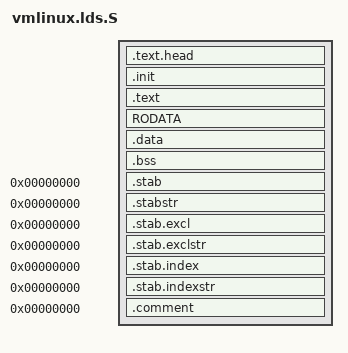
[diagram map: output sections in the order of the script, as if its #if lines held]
/* ld script to make ARM Linux kernel
 * taken from the i386 version by Russell King
 * Written by Martin Mares <mj@atrey.karlin.mff.cuni.cz>
 */

#include <asm-generic/vmlinux.lds.h>
#include <asm/thread_info.h>
#include <asm/memory.h>
	
OUTPUT_ARCH(arm)
ENTRY(stext)

#ifndef __ARMEB__
jiffies = jiffies_64;
#else
jiffies = jiffies_64 + 4;
#endif

SECTIONS
{
#ifdef CONFIG_XIP_KERNEL
	. = XIP_VIRT_ADDR(CONFIG_XIP_PHYS_ADDR);
#else
	. = PAGE_OFFSET + TEXT_OFFSET;
#endif
	.text.head : {
		_stext = .;
		_sinittext = .;
		*(.text.head)
	}

	.init : {			/* Init code and data		*/
			*(.init.text)
		_einittext = .;
		__proc_info_begin = .;
			*(.proc.info.init)
		__proc_info_end = .;
		__arch_info_begin = .;
			*(.arch.info.init)
		__arch_info_end = .;
		__tagtable_begin = .;
			*(.taglist.init)
		__tagtable_end = .;
		. = ALIGN(16);
		__setup_start = .;
			*(.init.setup)
		__setup_end = .;
		__early_begin = .;
			*(.early_param.init)
		__early_end = .;
		__initcall_start = .;
			INITCALLS
		__initcall_end = .;
		__con_initcall_start = .;
			*(.con_initcall.init)
		__con_initcall_end = .;
		__security_initcall_start = .;
			*(.security_initcall.init)
		__security_initcall_end = .;
#ifdef CONFIG_BLK_DEV_INITRD
		. = ALIGN(32);
		__initramfs_start = .;
			usr/built-in.o(.init.ramfs)
		__initramfs_end = .;
#endif
		. = ALIGN(4096);
		__per_cpu_start = .;
			*(.data.percpu)
			*(.data.percpu.shared_aligned)
		__per_cpu_end = .;
#ifndef CONFIG_XIP_KERNEL
		__init_begin = _stext;
		*(.init.data)
		. = ALIGN(4096);
		__init_end = .;
#endif
	}

	/DISCARD/ : {			/* Exit code and data		*/
		*(.exit.text)
		*(.exit.data)
		*(.exitcall.exit)
#ifndef CONFIG_MMU
		*(.fixup)
		*(__ex_table)
#endif
	}

	.text : {			/* Real text segment        */
        	_text = .; 		/* Text and read-only data  */
            *(.text.arm926_dma_clean_range)
            *(.text.arm926_dma_inv_range)
            *(.text.arm926_dma_flush_range)
            *(.text.__irq_svc)
            *(.text.__arch_copy_to_user)
            *(.text.__arch_copy_from_user)
            *(.text.__kmalloc)
            *(.text.OXNAS_unmask_irq)
            *(.text.local_bh_enable)
            *(.text.do_level_IRQ)
            *(.text.__memzero)
            *(.text.irq_exit)
            *(.text.__do_irq)
            *(.text.pfifo_fast_dequeue)
            *(.text.preempt_return)
            *(.text.cpu_arm926_switch_mm)
            *(.text.check_irq_lock)
            *(.text.tcp_init_tso_segs)
            *(.text.kfree_skbmem)
            *(.text.consistent_sync)
            *(.text.__alloc_skb)
            *(.text.skb_release_data)
            *(.text.OXNAS_mask_irq)
            *(.text.Ldiv0)
            *(.text.__do_softirq)
            *(.text.kmem_cache_free)
            *(.text.__kfree_skb)
            *(.text.kmem_cache_alloc)
            *(.text.radix_tree_lookup)
            *(.text.kfree)
            *(.text.asm_do_IRQ)
            *(.text.skb_clone)
            *(.text.qdisc_restart)
            *(.text.sock_wfree)
            *(.text.unlock_page)
            *(.text.tcp_cwnd_validate)
            *(.text.free_hot_cold_page)
            *(.text.memcpy)
            *(.text.velocity_free_tx_buf)
            *(.text.wake_up_bit)
            *(.text.cond_resched)
            *(.text.pfifo_fast_enqueue)
            *(.text.raise_softirq_irqoff)
            *(.text.tcp_push_one)
            *(.text.__modsi3)
            *(.text.update_send_head)
            *(.text.tcp_set_skb_tso_segs)
            *(.text.tcp_snd_test)
            *(.text.svc_preempt)
            *(.text.__tcp_select_window)
            *(.text.dev_queue_xmit)
            *(.text.oxnas_gettimeoffset)
            *(.text.__wake_up_bit)
            *(.text.mod_timer)
            *(.text.do_simple_IRQ)
            *(.text.velocity_xmit)
            *(.text.ip_output)
            *(.text.net_tx_action)
            *(.text.ip_queue_xmit)
            *(.text.tcp_cong_avoid)
            *(.text.sk_reset_timer)
            *(.text.velocity_intr)
            *(.text.pci_dma_sync_single_for_device)
            *(.text.process_backlog)
            *(.text.tcp_v4_send_check)
            *(.text.tcp_transmit_skb)
            *(.text.file_send_actor)
            *(.text.tcp_current_mss)
            *(.text.__netif_rx_schedule)
            *(.text.__muldi3)
            *(.text.release_sock)
            *(.text.do_softirq)
            *(.text.pfifo_fast_reset)
            *(.text.netif_rx)
            *(.text.kernel_sendmsg)
            *(.text.rt_hash_code)
            *(.text.mod_page_state_offset)
            *(.text.preempt_schedule)
            *(.text.inet_sendmsg)
            *(.text.page_waitqueue)
            *(.text.bictcp_acked)
            *(.text.__sk_dst_check)
            *(.text.blk_rq_map_sg)
            *(.text.tcp_mtu_to_mss)
            *(.text.__delay)
            *(.text.sock_sendmsg)
            *(.text.sock_sendpage)
            *(.text.ip_local_deliver)
            *(.text.bio_add_page)
            *(.text.tcp_sendmsg)
            *(.text.sock_no_sendpage)
            *(.text.__remove_from_page_cache)
            *(.text.net_rx_action)
            *(.text.eth_type_trans)
            *(.text.find_get_page)
            *(.text.netif_receive_skb)
            *(.text.verify_chain)
            *(.text.radix_tree_delete)
            *(.text.mpage_readpages)
            *(.text.velocity_rx_refill)
            *(.text.mpage_end_io_read)
            *(.text.radix_tree_insert)
            *(.text.ip_rcv)
            *(.text.register_gifconf)
            *(.text.dma_mmap)
            *(.text.tcp_rtt_estimator)
            *(.text.ox800sata_get_bbp_base)
            *(.text.mark_page_accessed)
            *(.text.update_process_times)
            *(.text.__pagevec_free)
            *(.text.read_page_state_offset)
            *(.text.__bio_add_page)
            *(.text.__pagevec_lru_add)
            *(.text.ox800sata_scr_read)
            *(.text.bio_add_pc_page)
            *(.text.__rcu_pending)
            *(.text.free_sg_entry)
            *(.text.put_page)
            *(.text.lock_timer_base)
            *(.text.radix_tree_tagged)
            *(.text.__lshrdi3)
            *(.text.lock_sock)
            *(.text.__udivsi3)
            *(.text.zone_watermark_ok)
            *(.text.klist_children_put)
            *(.text.sock_aio_dtor)
            *(.text.ata_qc_prep)
            *(.text.oxnas_dma_free)
            *(.text.rcu_pending)
            *(.text.free_cold_page)
            *(.text.get_page_from_freelist)
            *(.text.alloc_sg_entry)
            *(.text.ret_fast_syscall)
            *(.text.add_to_page_cache)
            *(.text.__mod_timer)
            *(.text.velocity_free_td_ring)
            *(.text.__do_div64)
            *(.text.remove_mapping)
            *(.text.fast_work_pending)
            *(.text.cond_resched_softirq)
            *(.text.tcp_v4_rcv)
            *(.text.kernel_recvmsg)
            *(.text.isolate_lru_pages)
            *(.text.klist_children_get)
            *(.text.sys_getpid)
            *(.text.mempool_free_slab)
            *(.text.kobject_get)
            *(.text.__tcp_push_pending_frames)
            *(.text.sk_stop_timer)
            *(.text.bictcp_state)
            *(.text.tcp_check_space)
            *(.text.kmem_cache_zalloc)
            *(.text.get_device)
            *(.text.work_pending)
            *(.text.tcp_ack)
            *(.text.do_edge_IRQ)
            *(.text.page_referenced)
            *(.text.profile_tick)
            *(.text.ox800sata_get_link_base)
            *(.text.__pagevec_release_nonlru)
            *(.text.blk_recount_segments)
            *(.text.__mod_page_state_offset)
            *(.text.linear_mergeable_bvec)
            *(.text.recalc_task_prio)
            *(.text.mempool_kmalloc)
            *(.text.do_mpage_readpage)
            *(.text.ksoftirqd)
            *(.text.__generic_unplug_device)
            *(.text.rt_cpu_seq_start)
            *(.text.bio_alloc)
            *(.text.tasklet_action)
            *(.text.effective_prio)
            *(.text.OXNAS_timer_interrupt)
            *(.text.__wake_up_common)
            *(.text.free_poll_entry)
            *(.text.vector_swi)
            *(.text.do_sock_read)
            *(.text.alloc_sg_controller)
            *(.text.tcp_rcv_established)
            *(.text.oxnas_dma_set_callback)
            *(.text.run_local_timers)
            *(.text.sock_rmalloc)
            *(.text.__rmqueue)
            *(.text.ox800sata_bmdma_start)
            *(.text.fget_light)
            *(.text.queue_work)
            *(.text.mempool_alloc_slab)
            *(.text.__wake_up)
            *(.text.default_idle)
            *(.text.fput)
            *(.text.add_wait_queue)
            *(.text.memcpy_toiovec)
            *(.text.rw_verify_area)
            *(.text.internal_add_timer)
            *(.text.hrtimer_run_queues)
            *(.text.tcp_v4_do_rcv)
            *(.text.raise_softirq)
            *(.text.del_timer)
            *(.text.try_to_wake_up)
            *(.text.__do_page_cache_readahead)
            *(.text.__alloc_pages)
            *(.text.sock_aio_read)
            *(.text.timer_tick)
            *(.text.ox800sata_check_status)
            *(.text.do_generic_mapping_read)
            *(.text.__ox800sata_scr_read)
            *(.text.elv_queue_empty)
            *(.text.do_select)
            *(.text.free_pages_bulk)
            *(.text.remove_wait_queue)
            *(.text.dma_bh)
            *(.text.__irq_usr)
            *(.text.vfs_read)
            *(.text.run_timer_softirq)
            *(.text.radix_tree_preload)
            *(.text.ptrace_getrn)
            *(.text.tcp_dsack_set)
            *(.text.__switch_to)
            *(.text.bio_hw_segments)
            *(.text.__const_udelay)
            *(.text.nr_running)
            *(.text.oxnas_dma_device_set_prd)
            *(.text.kref_put)
            *(.text.enqueue_task)
            *(.text.dequeue_task)
            *(.text.elv_next_request)
            *(.text.profile_hit)
            *(.text.slab_destroy)
            *(.text.schedule)
            *(.text.end_that_request_first)
            *(.text.cfq_find_next_crq)
            *(.text.__freed_request)
            *(.text.adjtime_adjustment)
            *(.text.bictcp_cong_avoid)
            *(.text.kthread_should_stop)
            *(.text.__activate_task)
            *(.text.account_system_time)
            *(.text.bio_fs_destructor)
            *(.text.mempool_alloc)
            *(.text.elv_set_request)
            *(.text.schedule_work)
            *(.text.wake_up_state)
            *(.text.encode_control_status)
            *(.text.alloc_skb_from_cache)
            *(.text.qdisc_lock_tree)
            *(.text.kref_get)
            *(.text.init_timer)
            *(.text.oxnas_dma_is_active)
            *(.text.shrink_slab)
            *(.text.poll_freewait)
            *(.text.sys_fstat64)
            *(.text.__pollwait)
            *(.text.cfq_queue_empty)
            *(.text.linear_issue_flush)
            *(.text.__tasklet_schedule)
            *(.text.ox800sata_get_io_base)
            *(.text.deactivate_task)
            *(.text.cleanup_rbuf)
            *(.text.nr_free_zone_pages)
            *(.text.ip_route_input)
            *(.text.__lock_page)
            *(.text.sock_poll)
            *(.text.__pskb_trim_head)
            *(.text.sys_read)
            *(.text.__arch_copy_to_user)
            *(.text.generic_make_request)
            *(.text.scsi_end_request)
            *(.text.bio_init)
            *(.text.pipefs_delete_dentry)
            *(.text.ox800sata_post_set_mode)
            *(.text.sock_common_recvmsg)
            *(.text.put_device)
            *(.text.tcp_syn_build_options)
            *(.text.scheduler_tick)
            *(.text.__sys_trace)
            *(.text.ox800sata_qc_new)
            *(.text.elv_latter_request)
            *(.text.do_sync_read)
            *(.text.ox800sata_spot_the_end)
            *(.text.get_dirty_limits)
            *(.text.bio_phys_segments)
            *(.text.vfs_fstat)
            *(.text.scsi_finish_command)
            *(.text.wake_up_process)
            *(.text.wdc_ledtrig_sata_activity)
            *(.text.__elv_add_request)
            *(.text.sock_common_setsockopt)
            *(.text.elv_may_queue)
            *(.text.rb_first)
            *(.text.dnotify_parent)
            *(.text.get_writeback_state)
            *(.text.__blk_put_request)
            *(.text.sock_mmap)
            *(.text.throttle_vm_writeout)
            *(.text.drive_stat_acct)
            *(.text.dlci_ioctl_set)
            *(.text.sys_send)
            *(.text.default_wake_function)
            *(.text.cfq_resort_rr_list)
            *(.text.bio_put)
            *(.text.scsi_done)
            *(.text.kobject_put)
            *(.text.release_pages)
            *(.text.ata_qc_issue)
            *(.text.cfq_dispatch_insert)
            *(.text.run_workqueue)
            *(.text.delayed_work_timer_fn)
            *(.text.scsi_init_cmd_errh)
            *(.text.alloc_sock_iocb)
            *(.text.blk_done_softirq)
            *(.text.do_timer)
            *(.text.scsi_10_lba_len)
            *(.text.scsi_device_unbusy)
            *(.text.bio_get_nr_vecs)
            *(.text.cfq_find_cfq_hash)
            *(.text.ata_dev_select)
            *(.text.blk_remove_plug)
            *(.text.end_that_request_last)
            *(.text.shrink_dcache_memory)
            *(.text.elv_put_request)
            *(.text.sys_sendto)
            *(.text.scsi_put_command)
            *(.text._clear_bit_le)
            *(.text.ata_rwcmd_protocol)
            *(.text.kobject_cleanup)
            *(.text.do_sendfile)
            *(.text.worker_thread)
            *(.text.elv_dispatch_sort)
            *(.text.tcp_fast_parse_options)
            *(.text.ox800sata_irq_on)
            *(.text.scsi_request_fn)
            *(.text.ox800sata_irq_handler)
            *(.text.nr_context_switches)
            *(.text.oxnas_dma_request)
            *(.text.sys_sendfile64)
            *(.text.cfq_add_crq_rb)
            *(.text.ata_scsi_queuecmd)
            *(.text.sock_def_readable)
            *(.text.inet_sendpage)
            *(.text.cfq_set_request)
            *(.text.init_request_from_bio)
            *(.text.tcp_v4_conn_request)
            *(.text.requeue_task)
            *(.text.cache_alloc_refill)
            *(.text.scsi_get_command)
            *(.text.blk_complete_request)
            *(.text.scsi_add_timer)
            *(.text.sk_stream_rfree)
            *(.text.__umodsi3)
            *(.text.ox800sata_tf_load)
            *(.text.tcp_recvmsg)
            *(.text.cfq_insert_request)
            *(.text.tcp_sendpage)
            *(.text.bio_alloc_bioset)
            *(.text.__tcp_ack_snd_check)
            *(.text.kthread_bind)
            *(.text.scsi_delete_timer)
            *(.text.ox800sata_dev_config)
            *(.text.add_wait_queue_exclusive)
            *(.text.ox800sata_bmdma_setup)
            *(.text.ox800sata_exec_command)
            *(.text.clear_queue_congested)
            *(.text.generic_file_sendfile)
            *(.text.get_io_context)
            *(.text.swap_buf_le16)
            *(.text._set_bit_be)
            *(.text.led_trigger_event)
            *(.text.current_io_context)
            *(.text.bio_free)
            *(.text.pipe_poll)
            *(.text.freed_request)
            *(.text.cfq_choose_req)
            *(.text.ox800sata_RAID_faults)
            *(.text.rb_prev)
            *(.text.blk_run_queue)
            *(.text.mpage_alloc)
            *(.text.__get_zone_counts)
            *(.text.mpage_bio_submit)
            *(.text.generic_fillattr)
            *(.text.kswapd)
            *(.text.preempt_schedule_irq)
            *(.text.mempool_free)
            *(.text.elv_dequeue_request)
            *(.text.add_interrupt_randomness)
            *(.text.poll_initwait)
            *(.text.__put_user_bad)
            *(.text.vfs_getattr)
            *(.text.scsi_free_sgtable)
            *(.text.laptop_sync_completion)
            *(.text.submit_bio)
            *(.text.sock_from_file)
            *(.text.add_disk_randomness)
            *(.text.scsi_kill_request)
            *(.text.free_hot_page)
            *(.text.bio_endio)
            *(.text.scsi_dispatch_cmd)
            *(.text.oxnas_dma_start)
            *(.text.cfq_remove_request)
            *(.text.do_gettimeofday)
            *(.text.skb_copy_datagram_iovec)
            *(.text.ext3_get_blocks_handle)
            *(.text.__down_read_trylock)
            *(.text.cfq_activate_request)
            *(.text.recalc_sigpending)
            *(.text.ext3_readpage)
            *(.text.ox800sata_dev_select)
            *(.text.ret_to_user)
            *(.text.elv_completed_request)
            *(.text.read_cache_page)
            *(.text.touch_atime)
            *(.text.cfq_update_next_crq)
            *(.text.no_work_pending)
            *(.text.recalc_sigpending_tsk)
            *(.text.end_that_request_chunk)
            *(.text.cp_new_stat64)
            *(.text.rb_next)
            *(.text.__wake_up_sync)
            *(.text.subsys_create_file)
            *(.text.rcu_needs_cpu)
            *(.text.sys_select)
            *(.text.oxnas_dma_device_set)
            *(.text.ata_sg_init)
            *(.text.__put_user_8)
            *(.text.ox800sata_port_disable)
            *(.text.scsi_next_command)
            *(.text.__scsi_done)
            *(.text.ata_scsi_qc_complete)
            *(.text.__wake_up_locked)
            *(.text.lru_add_drain)
            *(.text.bio_check_pages_dirty)
            *(.text.cascade)
            *(.text.tcp_poll)
            *(.text.oxnas_dma_set_common)
            *(.text.__pagevec_release)
            *(.text.ata_scsi_translate)
            *(.text.oxnas_dma_interrupt)
            *(.text.sys_newfstat)
            *(.text.tcp_send_delayed_ack)
            *(.text.scsi_decide_disposition)
            *(.text.ox800sata_qc_free)
            *(.text.scsi_softirq_done)
            *(.text.netlink_group_mask)
            *(.text.__brelse)
            *(.text.do_sock_write)
            *(.text.mempool_create_node)
            *(.text.ox800sata_qc_issue)
            *(.text.__scsi_release_request)
            *(.text.blockable_page_cache_readahead)
            *(.text.get_index)
            *(.text.walk_page_buffers)
            *(.text.__queue_work)
            *(.text.ret_from_fork)
            *(.text.mb_cache_shrink_fn)
            *(.text.sys_socketcall)
            *(.text.blk_congestion_wait)
            *(.text.put_io_context)
            *(.text.elevator_find)
            *(.text._set_bit_le)
            *(.text.generic_write_checks)
            *(.text.datagram_poll)
            *(.text.ext3_block_to_path)
            *(.text.scsi_prep_fn)
            *(.text.fget)
            *(.text.blk_plug_device)
            *(.text.disk_round_stats)
            *(.text.get_request)
            *(.text.page_cache_readahead)
            *(.text.__bread)
            *(.text.tcp_rcv_space_adjust)
            *(.text.ox800sata_tf_read)
            *(.text.add_timer_randomness)
            *(.text.sockfd_lookup_light)
            *(.text.__find_get_block)
            *(.text.split_page)
            *(.text.cfq_dispatch_requests)
            *(.text.cfq_kick_queue)
            *(.text.cfq_may_queue)
            *(.text.cfq_put_request)
            *(.text.get_request_wait)
            *(.text.default_callback)
            *(.text.cpu_arm926_set_pte)
            *(.text.tcp_event_data_recv)
            *(.text.ata_scsi_qc_new)
            *(.text.SetRoundingMode)
            *(.text.make_ahead_window)
            *(.text.inotify_inode_queue_event)
            *(.text.__make_request)
            *(.text.finish_wait)
            *(.text.cfq_completed_request)
            *(.text.__cfq_slice_expired)
            *(.text.sd_init_command)
            *(.text.find_lock_page)
            *(.text.pipefs_get_sb)
            *(.text.ata_qc_new_init)
            *(.text.task_timeslice)
            *(.text.sk_dst_check)
            *(.text.set_queue_congested)
            *(.text.prepare_to_wait)
            *(.text.sys_write)
            *(.text.swap_io_context)
            *(.text.sys_alarm)
            *(.text.mempool_resize)
            *(.text.__cond_resched)
            *(.text.scsi_16_lba_len)
            *(.text.autoremove_wake_function)
            *(.text.inotify_dentry_parent_queue_event)
            *(.text.cfq_init_prio_data)
            *(.text.group_send_sig_info)
            *(.text.ata_qc_issue_prot)
            *(.text.cfq_put_queue)
            *(.text.__set_irq_handler)
            *(.text.__generic_file_aio_read)
            *(.text.ox800sata_eng_timeout)
            *(.text.rb_erase)
            *(.text.generic_file_aio_read)
            *(.text.default_llseek)
            *(.text.blk_unplug_work)
            *(.text.linear_make_request)
            *(.text.elv_insert)
            *(.text.velocity_init_registers)
            *(.text.vfs_permission)
            *(.text.alloc_inode)
            *(.text.mii_ethtool_sset)
            *(.text.blk_rq_map_kern)
            *(.text.tcp_urg)
            *(.text.__ata_qc_complete)
            *(.text.io_schedule_timeout)
            *(.text.run_posix_cpu_timers)
            *(.text.ox800sata_irq_clear)
            *(.text.put_tty_driver)
            *(.text.free_sg_controller)
            *(.text.__sk_stream_mem_reclaim)
            *(.text.elv_merge)
            *(.text.scsi_run_queue)
            *(.text.elv_former_request)
            *(.text.blk_requeue_request)
            *(.text.__end_that_request_first)
            *(.text.ext3_get_block)
            *(.text.ox800sata_phy_reset)
            *(.text.schedule_timeout)
            *(.text.grab_cache_page_nowait)
            *(.text.bio_map_kern_endio)
            *(.text.__up_read)
            *(.text.tcp_data_queue)
            *(.text.set_bdev_super)
            *(.text.ext3_readpages)
            *(.text.scsi_exit_queue)
            *(.text.ext3_get_branch)
            *(.text.cfq_forced_dispatch_cfqqs)
            *(.text.bioset_free)
            *(.text.blk_execute_rq_nowait)
            *(.text.scsi_eh_wakeup)
            *(.text.tcp_delack_timer)
            *(.text.shrink_icache_memory)
            *(.text.mpage_end_io_write)
            *(.text.scsi_io_completion)
            *(.text.verify_iovec)
            *(.text.credit_entropy_store)
            *(.text.blk_unplug_timeout)
            *(.text.work_resched)
            *(.text.sys_sendfile)
            *(.text.do_bad_IRQ)
            *(.text.sd_rw_intr)
            *(.text.set_task_comm)
            *(.text.blk_do_ordered)
            *(.text.rb_last)
            *(.text.drop_buffers)
            *(.text.ata_scsi_rw_xlat)
            *(.text.oxnas_dma_shutdown)
            *(.text.__group_send_sig_info)
            *(.text.led_trigger_set_default)
            *(.text.blk_queue_bounce)
            *(.text.cfq_var_store)
            *(.text.rb_insert_color)
            *(.text.__remove_hrtimer)
            *(.text.sys_sysinfo)
            *(.text.tcp_simple_retransmit)
            *(.text.it_real_fn)
            *(.text.sk_send_sigurg)
            *(.text.sys_statfs64_wrapper)
            *(.text.alloc_page_buffers)
            *(.text.bio_pair_release)
            *(.text.__dequeue_signal)
            *(.text.kblockd_schedule_work)
            *(.text.wakeup_kswapd)
            *(.text.process_timeout)
            *(.text.__getblk)
            *(.text.blk_get_request)
            *(.text.sync_buffer)
            *(.text.sk_stream_mem_schedule)
            *(.text.vfs_stat)
            *(.text.rb_replace_node)
            *(.text.signal_wake_up)
            *(.text.ata_std_ports)
            *(.text.tcp_send_ack)
            *(.text.send_signal)
            *(.text._atomic_dec_and_lock)
            *(.text.set_bh_page)
            *(.text.mutex_trylock)
            *(.text.sys_sigaltstack_wrapper)
            *(.text.sig_ignored)
            *(.text.net_family_write_lock)
            *(.text.radix_tree_node_alloc)
            *(.text.may_open)
            *(.text.account_user_time)
            *(.text.udp_seq_start)
            *(.text.ll_front_merge_fn)
            *(.text.laptop_flush)
            *(.text.__tasklet_hi_schedule)
            *(.text.__und_usr)
            *(.text.do_signal)
            *(.text.wake_bit_function)
            *(.text.mutex_lock_interruptible)
            *(.text.cfq_merged_request)
            *(.text.scsi_init_cmd_from_req)
            *(.text.elv_requeue_request)
            *(.text.force_sigsegv)
            *(.text.elv_merge_requests)
            *(.text.cp_new_stat)
            *(.text.prepare_to_wait_exclusive)
            *(.text.ioc_set_batching)
            *(.text.check_kill_permission)
            *(.text.scsi_queue_insert)
            *(.text.__csum_ipv6_magic)
            *(.text.wb_kupdate)
            *(.text.__down_write_trylock)
            *(.text.elv_register_queue)
            *(.text.sys_getitimer)
            *(.text.ox800sata_pio_task)
            *(.text.hrtimer_try_to_cancel)
            *(.text.find_pid)
            *(.text.oxnas_dma_raw_isactive)
            *(.text.cmp_ex)
            *(.text.__mpage_writepage)
            *(.text.sk_stream_wait_memory)
            *(.text.sys_sched_yield)
            *(.text.background_writeout)
            *(.text.rotate_reclaimable_page)
            *(.text.do_sigaction)
            *(.text.sock_def_write_space)
            *(.text.sched_exit)
            *(.text.inode_change_ok)
            *(.text.wait_for_completion_interruptible)
            *(.text.device_initialize)
            *(.text.journal_set_revoke)
            *(.text.try_to_free_pages)
            *(.text.tcp_write_timer)
            *(.text.dev_ioctl)
            *(.text.skb_copy_expand)
            *(.text.invalidate_complete_page)
            *(.text.*)
			__exception_text_start = .;
			*(.exception.text)
			__exception_text_end = .;
			TEXT_TEXT
			SCHED_TEXT
			LOCK_TEXT
#ifdef CONFIG_MMU
			*(.fixup)
#endif
			*(.gnu.warning)
			*(.rodata)
			*(.rodata.*)
			*(.glue_7)
			*(.glue_7t)
		*(.got)			/* Global offset table		*/
	}

	RODATA

	_etext = .;			/* End of text and rodata section */

#ifdef CONFIG_XIP_KERNEL
	__data_loc = ALIGN(4);		/* location in binary */
	. = PAGE_OFFSET + TEXT_OFFSET;
#else
	. = ALIGN(THREAD_SIZE);
	__data_loc = .;
#endif

	.data : AT(__data_loc) {
		__data_start = .;	/* address in memory */

		/*
		 * first, the init task union, aligned
		 * to an 8192 byte boundary.
		 */
		*(.data.init_task)

#ifdef CONFIG_XIP_KERNEL
		. = ALIGN(4096);
		__init_begin = .;
		*(.init.data)
		. = ALIGN(4096);
		__init_end = .;
#endif

		. = ALIGN(4096);
		__nosave_begin = .;
		*(.data.nosave)
		. = ALIGN(4096);
		__nosave_end = .;

		/*
		 * then the cacheline aligned data
		 */
		. = ALIGN(32);
		*(.data.cacheline_aligned)

		/*
		 * The exception fixup table (might need resorting at runtime)
		 */
		. = ALIGN(32);
		__start___ex_table = .;
#ifdef CONFIG_MMU
		*(__ex_table)
#endif
		__stop___ex_table = .;

		/*
		 * and the usual data section
		 */
		DATA_DATA
		CONSTRUCTORS

		_edata = .;
	}
	_edata_loc = __data_loc + SIZEOF(.data);

	.bss : {
		__bss_start = .;	/* BSS				*/
		*(.bss)
		*(COMMON)
		_end = .;
	}
					/* Stabs debugging sections.	*/
	.stab 0 : { *(.stab) }
	.stabstr 0 : { *(.stabstr) }
	.stab.excl 0 : { *(.stab.excl) }
	.stab.exclstr 0 : { *(.stab.exclstr) }
	.stab.index 0 : { *(.stab.index) }
	.stab.indexstr 0 : { *(.stab.indexstr) }
	.comment 0 : { *(.comment) }
}

/*
 * These must never be empty
 * If you have to comment these two assert statements out, your
 * binutils is too old (for other reasons as well)
 */
ASSERT((__proc_info_end - __proc_info_begin), "missing CPU support")
ASSERT((__arch_info_end - __arch_info_begin), "no machine record defined")
